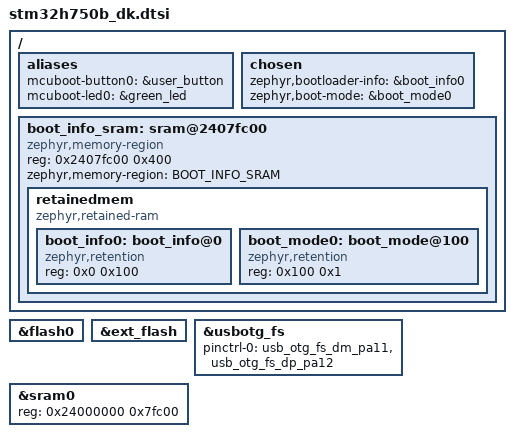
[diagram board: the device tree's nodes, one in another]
/* Delete Zephyr-default partitions before redefining them: the fork keeps
 * the bootloader in the 128 KB internal flash (the whole device -- there is
 * no room for an app slot after it) and XIPs the slots from the QSPI NOR's
 * memory-mapped window (0x90000000). The partitions dtsi included below hangs
 * the layout off ext_flash, the soc-nv-flash child of the QSPI controller;
 * the runtime flash driver is still the parent st,stm32-qspi-nor (flash_map
 * walks up the parent chain to find it).
 */
&flash0 {
	/delete-node/ partitions;
};

&ext_flash {
	/* Map the flash's child address space into the CPU's memory-mapped
	 * window so the mapped-partition reg addresses resolve absolutely (the
	 * partitions node below only carries an empty `ranges;`). The upstream
	 * controller already maps its own child space to 0x90000000; this
	 * mirrors it on the flash device itself, as the zephyr,mapped-partition
	 * binding requires of the NVM memory node.
	 */
	#address-cells = <1>;
	#size-cells = <1>;
	ranges = <0x0 0x90000000 DT_SIZE_M(128)>;

	/delete-node/ partitions;
};

/* Enable the OTG FS controller for the bootloader's UF2 drive. The board
 * overlay in the application enables it as well; this keeps the bootloader
 * image self-contained (USBD_DEVICE_DEFINE links against the node's device).
 */
zephyr_udc0: &usbotg_fs {
	pinctrl-0 = <&usb_otg_fs_dm_pa11 &usb_otg_fs_dp_pa12>;
	pinctrl-names = "default";
	status = "okay";
};

/ {
	aliases {
		mcuboot-button0 = &user_button;
		mcuboot-led0 = &green_led;
	};
};

#include "stm32h750b_dk-partitions.dtsi"

/* Flash chosen properties needed by both builds:
 * - zephyr,flash mirrors upstream (the XIP flash: the STM32 soc layer derives
 *   the linker's flash base from it, and the imgtool signing step in
 *   deps/zephyr/cmake/mcuboot.cmake reads write-block-size from it).
 * - zephyr,code-partition is deliberately not set here -- upstream's
 *   ext_flash_app variant dts points it at slot0_partition for XIP
 *   applications (the label is re-defined by the partitions dtsi above), and
 *   boot/zephyr/app.overlay points it at boot_partition (internal flash) for
 *   the bootloader.
 */
/* Bootloader info shared-data area: the last KB of this board's RAM, kept
 * out of the managed RAM so neither image clobbers it. The bootloader
 * writes its boot state here on every boot (BOOT_SHARE_DATA_BOOTINFO ->
 * BLINFO TLVs via boot_write_shared_data()); the application reads the
 * same region to answer the SMP bootloader-info command (RETENTION_
 * BOOTLOADER_INFO_TYPE_MCUBOOT). Carved here because this dtsi applies to
 * both images.
 *
 * A second, one-byte retention cell in the same block backs the boot-mode
 * flag (zephyr,boot-mode): the application sets it to request the
 * bootloader's update mode (reset_to_bootloader() / RunMode.UF2) and the
 * bootloader reads and clears it at boot (io_detect_boot_mode()). SRAM
 * content survives the warm reset that follows the request, which is all a
 * button-less entrance needs; a power cycle simply drops the request.
 */
&sram0 {
	reg = <0x24000000 0x7fc00>;
};

/ {
	chosen {
		zephyr,bootloader-info = &boot_info0;
		zephyr,boot-mode = &boot_mode0;
	};

	boot_info_sram: sram@2407fc00 {
		compatible = "zephyr,memory-region", "mmio-sram";
		reg = <0x2407fc00 0x400>;
		zephyr,memory-region = "BOOT_INFO_SRAM";
		status = "okay";

		retainedmem {
			compatible = "zephyr,retained-ram";
			status = "okay";
			#address-cells = <1>;
			#size-cells = <1>;

			boot_info0: boot_info@0 {
				compatible = "zephyr,retention";
				status = "okay";
				reg = <0x0 0x100>;
			};

			boot_mode0: boot_mode@100 {
				compatible = "zephyr,retention";
				status = "okay";
				reg = <0x100 0x1>;
			};
		};
	};
};
